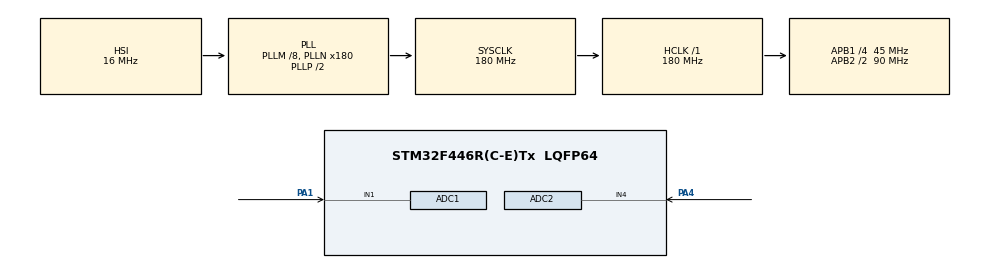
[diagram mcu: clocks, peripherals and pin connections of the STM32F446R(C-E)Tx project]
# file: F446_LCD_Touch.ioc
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ADC1.Channel-6\#ChannelRegularConversion=ADC_CHANNEL_1
ADC1.NbrOfConversionFlag=1
ADC1.Rank-6\#ChannelRegularConversion=1
ADC1.SamplingTime-6\#ChannelRegularConversion=ADC_SAMPLETIME_3CYCLES
ADC1.master=1
ADC2.Channel-7\#ChannelRegularConversion=ADC_CHANNEL_4
ADC2.NbrOfConversionFlag=1
ADC2.Rank-7\#ChannelRegularConversion=1
ADC2.SamplingTime-7\#ChannelRegularConversion=ADC_SAMPLETIME_3CYCLES
Mcu.Family=STM32F4
Mcu.Name=STM32F446R(C-E)Tx
Mcu.Package=LQFP64
NVIC.PriorityGroup=NVIC_PRIORITYGROUP_0
PA1.Signal=ADCx_IN1
PA13.GPIO_Label=TMS
PA13.Mode=Serial_Wire
PA13.Signal=SYS_JTMS-SWDIO
PA14.GPIO_Label=TCK
PA14.Mode=Serial_Wire
PA14.Signal=SYS_JTCK-SWCLK
PA4.Signal=ADCx_IN4
PB3.GPIO_Label=SWO
PB3.Signal=SYS_JTDO-SWO
PC14-OSC32_IN.Mode=LSE-External-Oscillator
PC14-OSC32_IN.Signal=RCC_OSC32_IN
PC15-OSC32_OUT.Mode=LSE-External-Oscillator
PC15-OSC32_OUT.Signal=RCC_OSC32_OUT
PH0-OSC_IN.Mode=HSE-External-Oscillator
PH0-OSC_IN.Signal=RCC_OSC_IN
PH1-OSC_OUT.Mode=HSE-External-Oscillator
PH1-OSC_OUT.Signal=RCC_OSC_OUT
ProjectManager.HeapSize=0x200
ProjectManager.StackSize=0x400
ProjectManager.TargetToolchain=Makefile
RCC.48MHZClocksFreq_Value=84000000
RCC.AHBFreq_Value=180000000
RCC.APB1CLKDivider=RCC_HCLK_DIV4
RCC.APB1Freq_Value=45000000
RCC.APB1TimFreq_Value=90000000
RCC.APB2CLKDivider=RCC_HCLK_DIV2
RCC.APB2Freq_Value=90000000
RCC.APB2TimFreq_Value=180000000
RCC.CortexFreq_Value=180000000
RCC.FLatency-AdvancedSettings=FLASH_LATENCY_5
RCC.HCLKFreq_Value=180000000
RCC.HSE_VALUE=8000000
RCC.HSI_VALUE=16000000
RCC.PLLM=8
RCC.PLLN=180
RCC.SYSCLKFreq_VALUE=180000000
RCC.SYSCLKSource=RCC_SYSCLKSOURCE_PLLCLK
RCC.USBFreq_Value=180000000
RCC.VCOOutputFreq_Value=360000000
SH.ADCx_IN1.0=ADC1_IN1,IN1
SH.ADCx_IN4.0=ADC2_IN4,IN4
board=NUCLEO-F446RE

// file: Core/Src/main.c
/* USER CODE BEGIN Header */
/**
  ******************************************************************************
  * @file           : main.c
  * @brief          : Main program body
  ******************************************************************************
  ** This notice applies to any and all portions of this file
  * that are not between comment pairs USER CODE BEGIN and
  * USER CODE END. Other portions of this file, whether
  * inserted by the user or by software development tools
  * are owned by their respective copyright owners.
  *
  * COPYRIGHT(c) 2019 STMicroelectronics
  *
  * Redistribution and use in source and binary forms, with or without modification,
  * are permitted provided that the following conditions are met:
  *   1. Redistributions of source code must retain the above copyright notice,
  *      this list of conditions and the following disclaimer.
  *   2. Redistributions in binary form must reproduce the above copyright notice,
  *      this list of conditions and the following disclaimer in the documentation
  *      and/or other materials provided with the distribution.
  *   3. Neither the name of STMicroelectronics nor the names of its contributors
  *      may be used to endorse or promote products derived from this software
  *      without specific prior written permission.
  *
  * THIS SOFTWARE IS PROVIDED BY THE COPYRIGHT HOLDERS AND CONTRIBUTORS "AS IS"
  * AND ANY EXPRESS OR IMPLIED WARRANTIES, INCLUDING, BUT NOT LIMITED TO, THE
  * IMPLIED WARRANTIES OF MERCHANTABILITY AND FITNESS FOR A PARTICULAR PURPOSE ARE
  * DISCLAIMED. IN NO EVENT SHALL THE COPYRIGHT HOLDER OR CONTRIBUTORS BE LIABLE
  * FOR ANY DIRECT, INDIRECT, INCIDENTAL, SPECIAL, EXEMPLARY, OR CONSEQUENTIAL
  * DAMAGES (INCLUDING, BUT NOT LIMITED TO, PROCUREMENT OF SUBSTITUTE GOODS OR
  * SERVICES; LOSS OF USE, DATA, OR PROFITS; OR BUSINESS INTERRUPTION) HOWEVER
  * CAUSED AND ON ANY THEORY OF LIABILITY, WHETHER IN CONTRACT, STRICT LIABILITY,
  * OR TORT (INCLUDING NEGLIGENCE OR OTHERWISE) ARISING IN ANY WAY OUT OF THE USE
  * OF THIS SOFTWARE, EVEN IF ADVISED OF THE POSSIBILITY OF SUCH DAMAGE.
  *
  ******************************************************************************
  */
/* USER CODE END Header */
#include "main.h"
#include "adc.h"
#include "gpio.h"

/* USER CODE BEGIN Includes */
#include "lcd.h"
#include "lcd_touch.h"
/* USER CODE END Includes */

void SystemClock_Config(void);

/* USER CODE BEGIN 0 */

/**
 * Draws two last subsequent touches in a line.
 */

/* USER CODE END 0 */

int main(void)
{

  /* MCU Configuration--------------------------------------------------------*/

  /* Reset of all peripherals, Initializes the Flash interface and the Systick. */
  HAL_Init();

  /* Configure the system clock */
  SystemClock_Config();

  /* Initialize all configured peripherals */
  MX_GPIO_Init();
  MX_ADC1_Init();
  MX_ADC2_Init();
  /* USER CODE BEGIN 2 */

	LCD_Init();
	LCD_FillScreen(BLACK);
	LCD_SetTextSize(3);
	LCD_SetTextColor(GREEN, BLACK);

	LCD_Touch_Init(&hadc2, ADC_CHANNEL_4, &hadc1, ADC_CHANNEL_1);
	LCD_SetMode(LCD_MODE_TOUCH);
	LCD_TouchPoint p;
  /* USER CODE END 2 */

  /* Infinite loop */
  /* USER CODE BEGIN WHILE */

  while (1)
  {
	  if (LCD_Touch_Read(&p) == LCD_TOUCH_READ_SUCCESS) {
		  LCD_Touch_Draw_ConnectLastPoint(&p);
		  LCD_Touch_Draw_PrintInfo();
	  }
	  LCD_Touch_Draw_Update();
    /* USER CODE END WHILE */

  }
}

void SystemClock_Config(void)
{
  RCC_OscInitTypeDef RCC_OscInitStruct = {0};
  RCC_ClkInitTypeDef RCC_ClkInitStruct = {0};

  /** Configure the main internal regulator output voltage
  */
  __HAL_RCC_PWR_CLK_ENABLE();
  __HAL_PWR_VOLTAGESCALING_CONFIG(PWR_REGULATOR_VOLTAGE_SCALE1);
  /** Initializes the RCC Oscillators according to the specified parameters
  * in the RCC_OscInitTypeDef structure.
  */
  RCC_OscInitStruct.OscillatorType = RCC_OSCILLATORTYPE_HSI;
  RCC_OscInitStruct.HSIState = RCC_HSI_ON;
  RCC_OscInitStruct.HSICalibrationValue = RCC_HSICALIBRATION_DEFAULT;
  RCC_OscInitStruct.PLL.PLLState = RCC_PLL_ON;
  RCC_OscInitStruct.PLL.PLLSource = RCC_PLLSOURCE_HSI;
  RCC_OscInitStruct.PLL.PLLM = 8;
  RCC_OscInitStruct.PLL.PLLN = 180;
  RCC_OscInitStruct.PLL.PLLP = RCC_PLLP_DIV2;
  RCC_OscInitStruct.PLL.PLLQ = 2;
  RCC_OscInitStruct.PLL.PLLR = 2;
  if (HAL_RCC_OscConfig(&RCC_OscInitStruct) != HAL_OK)
  {
    Error_Handler();
  }
  /** Activate the Over-Drive mode
  */
  if (HAL_PWREx_EnableOverDrive() != HAL_OK)
  {
    Error_Handler();
  }
  /** Initializes the CPU, AHB and APB buses clocks
  */
  RCC_ClkInitStruct.ClockType = RCC_CLOCKTYPE_HCLK|RCC_CLOCKTYPE_SYSCLK
                              |RCC_CLOCKTYPE_PCLK1|RCC_CLOCKTYPE_PCLK2;
  RCC_ClkInitStruct.SYSCLKSource = RCC_SYSCLKSOURCE_PLLCLK;
  RCC_ClkInitStruct.AHBCLKDivider = RCC_SYSCLK_DIV1;
  RCC_ClkInitStruct.APB1CLKDivider = RCC_HCLK_DIV4;
  RCC_ClkInitStruct.APB2CLKDivider = RCC_HCLK_DIV2;

  if (HAL_RCC_ClockConfig(&RCC_ClkInitStruct, FLASH_LATENCY_5) != HAL_OK)
  {
    Error_Handler();
  }
}

void Error_Handler(void)
{
}

/************************ (C) COPYRIGHT STMicroelectronics *****END OF FILE****/
